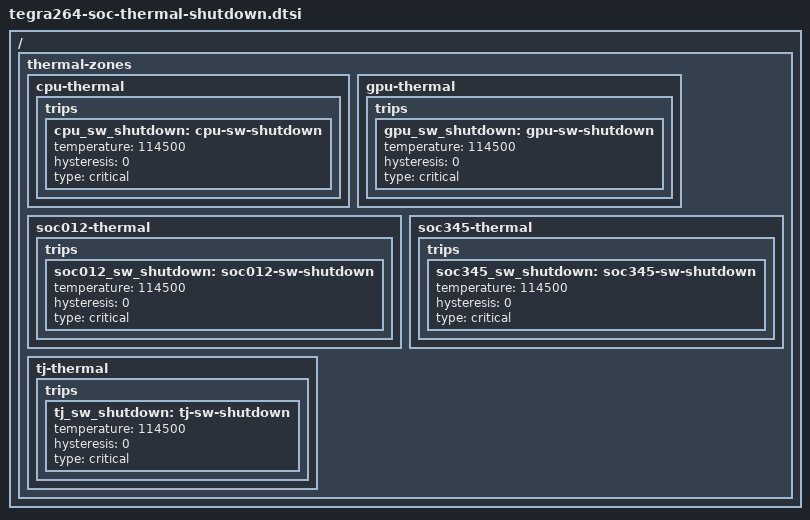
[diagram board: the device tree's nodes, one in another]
// SPDX-License-Identifier: GPL-2.0-only
// SPDX-FileCopyrightText: Copyright (c) 2024-2025, NVIDIA CORPORATION & AFFILIATES.  All rights reserved.

/ {
	thermal-zones {
		cpu-thermal {
			trips {
				cpu_sw_shutdown: cpu-sw-shutdown {
					temperature = <114500>;
					hysteresis = <0>;
					type = "critical";
				};
			};
		};

		gpu-thermal {
			trips {
				gpu_sw_shutdown: gpu-sw-shutdown {
					temperature = <114500>;
					hysteresis = <0>;
					type = "critical";
				};
			};
		};

		soc012-thermal {
			trips {
				soc012_sw_shutdown: soc012-sw-shutdown {
					temperature = <114500>;
					hysteresis = <0>;
					type = "critical";
				};
			};
		};

		soc345-thermal {
			trips {
				soc345_sw_shutdown: soc345-sw-shutdown {
					temperature = <114500>;
					hysteresis = <0>;
					type = "critical";
				};
			};
		};

		tj-thermal {
			trips {
				tj_sw_shutdown: tj-sw-shutdown {
					temperature = <114500>;
					hysteresis = <0>;
					type = "critical";
				};
			};
		};
	};
};
